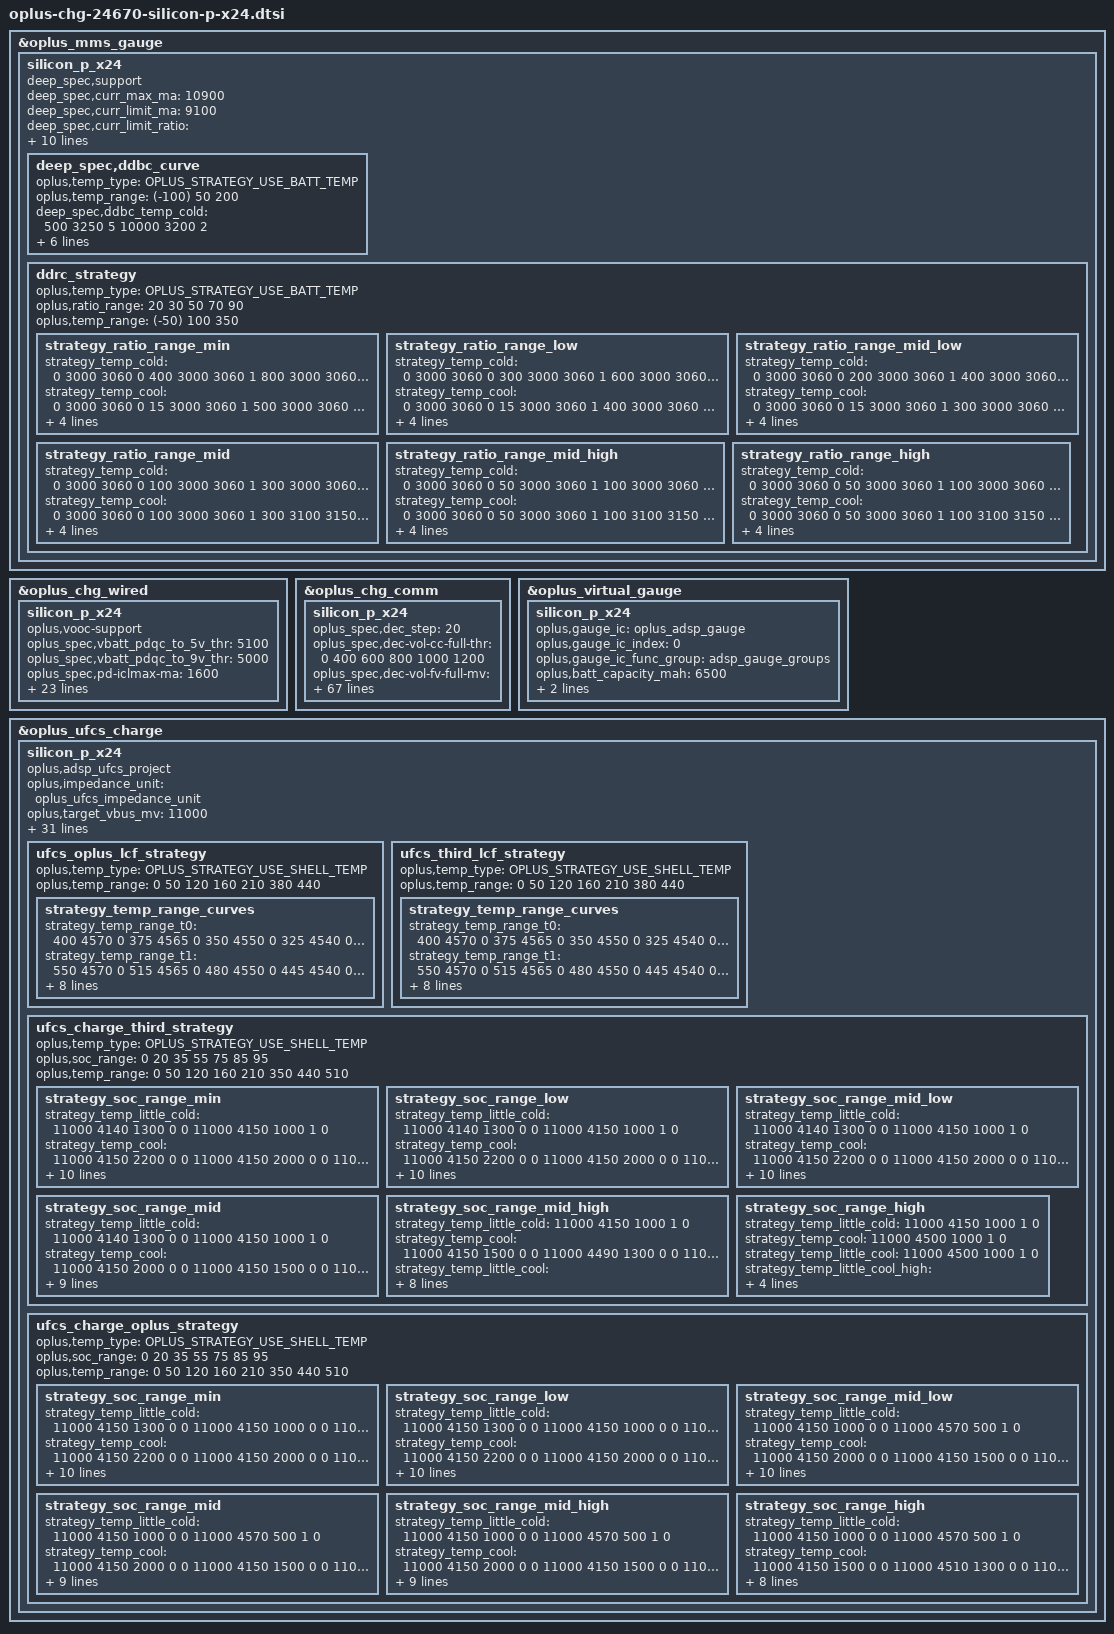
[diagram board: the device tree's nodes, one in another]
//ifdef OPLUS_FEATURE_CHG_BASIC

&oplus_mms_gauge {
	silicon_p_x24 {
		deep_spec,support;

		deep_spec,curr_max_ma = <10900>;
		deep_spec,curr_limit_ma = <9100>;
		deep_spec,curr_limit_ratio = <20 100 0
					50 30 1
					500 60 2
					500 60 3>;

		deep_spec,uv_thr = <3000>;
		deep_spec,count_thr = <50>;
		deep_spec,vbat_soc = <20>;
		deep_spec,count_step = <0 10 0
					350 12 1
					450 15 2
					530 20 3>;

		deep_spec,term_coeff = <3000 320 0
					3050 440 2
					3060 440 2
					3150 540 4
					3250 580 5
					3350 600 7>;
		deep_spec,ddrc_strategy_name = "ddrc_curve";
		deep_spec,volt_step = <20>;
		deep_spec,ddbc_curve {
			oplus,temp_type = <OPLUS_STRATEGY_USE_BATT_TEMP>;
			oplus,temp_range = <(-100) 50 200>;
			deep_spec,ddbc_temp_cold = <500 3250 5
						   10000 3200 2>;
			deep_spec,ddbc_temp_cool = <500 3250 5
						   10000 3200 2>;
			deep_spec,ddbc_temp_normal = <500 3350 5
						   10000 3300 2>;
			deep_spec,ddbc_temp_warm = <500 3350 5
						   10000 3300 2>;
		};
		ddrc_strategy {
			oplus,temp_type = <OPLUS_STRATEGY_USE_BATT_TEMP>;
			oplus,ratio_range = <20 30 50 70 90>;
			oplus,temp_range = <(-50) 100 350>;
			strategy_ratio_range_min {
				strategy_temp_cold =	<0 3000 3060 0
							400 3000 3060 1
							800 3000 3060 2
							1200 3100 3150 3
							1600 3200 3250 4
							2000 3300 3350 5>;
				strategy_temp_cool =	<0 3000 3060 0
							15 3000 3060 1
							500 3000 3060 2
							1000 3100 3150 3
							1500 3200 3250 4
							2000 3300 3350 5>;
				strategy_temp_normal =	<0 3000 3060 0
							15 3000 3060 1
							500 3100 3150 2
							1000 3200 3250 3
							1500 3300 3350 4>;
				strategy_temp_warm =	<0 3000 3060 0
							15 3000 3060 1
							500 3100 3150 2
							1000 3200 3250 3
							1500 3300 3350 4>;
			};
			strategy_ratio_range_low {
				strategy_temp_cold =	<0 3000 3060 0
							300 3000 3060 1
							600 3000 3060 2
							900 3100 3150 3
							1200 3200 3250 4
							1600 3300 3350 5>;
				strategy_temp_cool =	<0 3000 3060 0
							15 3000 3060 1
							400 3000 3060 2
							800 3100 3150 3
							1200 3200 3250 4
							1600 3300 3350 5 >;
				strategy_temp_normal =	<0 3000 3060 0
							15 3000 3060 1
							400 3100 3150 2
							800 3200 3250 3
							1200 3300 3350 4>;
				strategy_temp_warm =	<0 3000 3060 0
							15 3000 3060 1
							400 3100 3150 2
							800 3200 3250 3
							1200 3300 3350 4>;
			};
			strategy_ratio_range_mid_low {
				strategy_temp_cold =	<0 3000 3060 0
							200 3000 3060 1
							400 3000 3060 2
							600 3100 3150 3
							900 3200 3250 4
							1200 3300 3350 5>;
				strategy_temp_cool =	<0 3000 3060 0
							15 3000 3060 1
							300 3000 3060 2
							600 3100 3150 3
							900 3200 3250 4
							1200 3300 3350 5>;
				strategy_temp_normal =	<0 3000 3060 0
							15 3000 3060 1
							300 3100 3150 2
							600 3200 3250 3
							900 3300 3350 4>;
				strategy_temp_warm =	<0 3000 3060 0
							15 3000 3060 1
							300 3100 3150 2
							600 3200 3250 3
							900 3300 3350 4>;
			};
			strategy_ratio_range_mid {
				strategy_temp_cold =	<0 3000 3060 0
							100 3000 3060 1
							300 3000 3060 2
							500 3100 3150 3
							700 3200 3250 4
							900 3300 3350 5>;
				strategy_temp_cool =	<0 3000 3060 0
							100 3000 3060 1
							300 3100 3150 2
							600 3200 3250 3
							900 3300 3350 4>;
				strategy_temp_normal =	<0 3000 3060 0
							100 3100 3150 1
							300 3200 3250 2
							600 3300 3350 3>;
				strategy_temp_warm =	<0 3000 3060 0
							100 3100 3150 1
							300 3200 3250 2
							600 3300 3350 3>;
			};
			strategy_ratio_range_mid_high {
				strategy_temp_cold =	<0 3000 3060 0
							50 3000 3060 1
							100 3000 3060 2
							150 3100 3150 3
							300 3200 3250 4
							500 3300 3350 5>;
				strategy_temp_cool =	<0 3000 3060 0
							50 3000 3060 1
							100 3100 3150 2
							150 3200 3250 3
							300 3300 3350 4>;
				strategy_temp_normal =	<0 3000 3060 0
							50 3100 3150 1
							100 3200 3250 2
							150 3300 3350 3>;
				strategy_temp_warm =	<0 3000 3060 0
							50 3100 3150 1
							100 3200 3250 2
							150 3300 3350 3>;
			};
			strategy_ratio_range_high {
				strategy_temp_cold =	<0 3000 3060 0
							50 3000 3060 1
							100 3000 3060 2
							150 3100 3150 3
							300 3200 3250 4
							500 3300 3350 5>;
				strategy_temp_cool =	<0 3000 3060 0
							50 3000 3060 1
							100 3100 3150 2
							150 3200 3250 3
							300 3300 3350 4>;
				strategy_temp_normal =	<0 3000 3060 0
							50 3100 3150 1
							100 3200 3250 2
							150 3300 3350 3>;
				strategy_temp_warm =	<0 3000 3060 0
							50 3100 3150 1
							100 3200 3250 2
							150 3300 3350 3>;
			};
		};
	};
};


&oplus_chg_wired {
	silicon_p_x24 {
		oplus,vooc-support;

		oplus_spec,vbatt_pdqc_to_5v_thr = <5100>;
		oplus_spec,vbatt_pdqc_to_9v_thr = <5000>;
		oplus_spec,pd-iclmax-ma = <1600>;
		oplus_spec,qc-iclmax-ma = <1600>;
		oplus_spec,non-standard-ibatmax-ma = <500>;
		oplus_spec,input-power-mw = <
			2500		/* OPLUS_WIRED_CHG_MODE_UNKNOWN */
			2500		/* OPLUS_WIRED_CHG_MODE_SDP */
			7500		/* OPLUS_WIRED_CHG_MODE_CDP */
			10000		/* OPLUS_WIRED_CHG_MODE_DCP */
			15000		/* OPLUS_WIRED_CHG_MODE_VOOC */
			14400		/* OPLUS_WIRED_CHG_MODE_QC */
			14400		/* OPLUS_WIRED_CHG_MODE_PD */
		>;
		oplus_spec,led_on-fccmax-ma = <0 273 1364 1760 1760 1760 1760 500 0>;
		oplus_spec,fccmax-ma-lv = <
			0 273 1100 1100 1100 1100 1100 1100  0	/* OPLUS_WIRED_CHG_MODE_UNKNOWN */
			0 273  300  300  300  300  300  300  0	/* OPLUS_WIRED_CHG_MODE_SDP */
			0 273  800  800  800  800  800  800  0	/* OPLUS_WIRED_CHG_MODE_CDP */
			0 273  1100 1100 1100 1100 1100 1100 0	/* OPLUS_WIRED_CHG_MODE_DCP */
			0 273  1364 1650 1650 1650 1650 1650 0	/* OPLUS_WIRED_CHG_MODE_VOOC */
			0 273  1364 1760 1760 1760 1760 1667 0	/* OPLUS_WIRED_CHG_MODE_QC */
			0 273  1364 1760 1760 1760 1760 1667 0	/* OPLUS_WIRED_CHG_MODE_PD */
		>;
		oplus_spec,fccmax-ma-hv = <
			0 273  545  818 1100 1100 1100  1100 0	/* OPLUS_WIRED_CHG_MODE_UNKNOWN */
			0 273  300  300  300  300  300  300  0	/* OPLUS_WIRED_CHG_MODE_SDP */
			0 273  545  800  800  800  800  800  0	/* OPLUS_WIRED_CHG_MODE_CDP */
			0 273  545  818  1100 1100 1100 1100 0	/* OPLUS_WIRED_CHG_MODE_DCP */
			0 273  545  818  1364 1650 1650 1650 0	/* OPLUS_WIRED_CHG_MODE_VOOC */
			0 273  545  818  1364 1760 1760 1667 0	/* OPLUS_WIRED_CHG_MODE_QC */
			0 273  545  818  1364 1760 1760 1667 0	/* OPLUS_WIRED_CHG_MODE_PD */
		>;

		oplus_spec,cool_down_pdqc_vol_mv = <9000 9000 9000>;
		oplus_spec,cool_down_pdqc_curr_ma = <1200 1600 1600>;
		oplus_spec,cool_down_vooc_curr_ma = <1200 1500 2000 2500 3000 3000>;
		oplus_spec,cool_down_normal_curr_ma = <1200 1500 2000>;

		oplus_spec,vbus_ov_thr_mv = <11000 11000>;
		oplus_spec,vbus_uv_thr_mv = <4300 4300>;

		/* first data is strategy used temp type */
		oplus,vooc_strategy_name = "cgcl";
		oplus,vooc_strategy_data = <OPLUS_STRATEGY_USE_BATT_TEMP
					    0   350 3600 1 0
					    330 370 3200 2 0
					    350 440 2200 2 1>;
	};
};
&oplus_chg_comm {
	silicon_p_x24 {
		oplus_spec,dec_step = <20>;
		oplus_spec,dec-vol-cc-full-thr = <0 400 600 800 1000 1200>;
		oplus_spec,dec-vol-fv-full-mv = <0 20 20 40 40 40>;
		oplus_spec,batt-them-thr = <(-100) 0 50 120 160 350 450 530>;
		oplus_spec,iterm-ma = <162>;
		oplus_spec,fv-mv = <4500 4500 4500 4500 4500 4500 4475 4130 4130>;
		oplus_spec,sw-fv-mv = <4450 4450 4450 4450 4450 4450 4425 4080 4080>;
		oplus_spec,hw-fv-inc-mv = <0 18 18 18 18 18 18 18 0>;
		oplus_spec,sw-over-fv-mv = <4510 4510 4510 4510 4510 4510 4485 4140 4140>;
		oplus_spec,sw-over-fv-dec-mv = <8>;
		oplus_spec,non-standard-sw-fv-mv = <3930>;
		oplus_spec,non-standard-fv-mv = <3980>;
		oplus_spec,non-standard-hw-fv-inc-mv = <18>;
		oplus_spec,non-standard-sw-over-fv-mv = <3990>;
		oplus_spec,non-standard-vbatdet-mv = <3680>;
		oplus_spec,wired-vbatdet-mv = <0 4200 4300 4400 4400 4400 4375 4030 0>;
		oplus_spec,fcc-gear-thr-mv = <4180>;
		oplus_spec,fcc-gear-shake-mv = <400 400 400 300 300 180 180 180 180>;
		oplus_spec,vbatt-ov-thr-mv = <4600>;

		oplus_spec,full_pre_ffc_judge;
		oplus_spec,full-pre-ffc-mv = <4495>;
		oplus_spec,ffc-temp-thr = <120 210 350 440>;
		oplus_spec,wired-ffc-step-max = <2>;
		oplus_spec,wired-ffc-fv-mv = <4590 4590>;

		oplus_spec,wired-ffc-fv-cutoff-mv = <4550 4525 4490
						     4520 4505 4475>;

		oplus_spec,removed_bat_decidegc = <390>;

		oplus_spec,wired-ffc-fcc-ma = <550 550 550
					       350 350 350>;
		oplus_spec,wired-ffc-fcc-cutoff-ma = <400 400 400
						      200 200 200>;

		oplus_spec,drop_soc_2_temp_ladder = <(-50) 0 0 0 0 0 0 0 0 0>;
		oplus_spec,volt_diff_ladder_of_drop_soc_2 = <20 50 0 0 0 0 0 0 0 0>;
		oplus_spec,keep_soc_2_temp_ladder = <(-200) (-50) 0 0 0 0 0 0 0 0>;
		oplus_spec,volt_diff_ladder_of_keep_soc_2 = <10 20 30 0 0 0 0 0 0 0>;
		oplus_spec,back_rm_of_drop_soc_2 = <60>;
		oplus_spec,back_rm_of_drop_soc_1 = <60>;
		oplus_spec,load_current_of_drop_soc_2 = <500>;
		oplus_spec,load_current_of_drop_soc_1 = <1000>;
		oplus_spec,current_limit_of_drop_soc_2 = <350>;
		oplus_spec,volt_of_fast_drop_soc_1 = <2900>;
		oplus_spec,support_uisoc_low_battery_control;


		oplus_spec,vbat_uv_thr_mv = <3000>;
		oplus_spec,vbat_charging_uv_thr_mv = <2900>;

		/*If use subboard NTC as battery temp, config it as 20, otherwise 0 */
		oplus_spec,tbatt_power_off_cali_temp = <0>;
		oplus,vooc_show_ui_soc_decimal;
		oplus_spec,poweroff_high_batt_temp = <720>;
		oplus_spec,poweroff_emergency_batt_temp = <770>;
		oplus,ui_soc_decimal_speedmin = <20>;

		oplus,gauge_stuck_jump_support;
		oplus,gauge_stuck_threshold = <15>;
		oplus,gauge_stuck_time = <50>;

		oplus_spec,sw_check_full_cnt = <12>;
		oplus,hidden_soc_switch;
		oplus,reserve_chg_soc = <3>;
		oplus,hidden_soc_percent = <20>;


		oplus,ui_soc_2_voltage_comp_mv = <30>;
		oplus,chg_shutdown_max_mv = <3000>;
	};
};

&oplus_virtual_gauge {
	silicon_p_x24 {
			oplus,gauge_ic = <&oplus_adsp_gauge>;
			oplus,gauge_ic_index = <0>;
			oplus,gauge_ic_func_group = <&adsp_gauge_groups>;
			oplus,batt_capacity_mah = <6500>;
			oplus,ic_type = <OPLUS_CHG_IC_VIRTUAL_GAUGE>;
			oplus,ic_index = <0>;
	};
};
&oplus_ufcs_charge {
	silicon_p_x24 {
		oplus,adsp_ufcs_project;
		oplus,impedance_unit = <&oplus_ufcs_impedance_unit>;

		oplus,target_vbus_mv = <11000>;
		oplus,curr_max_ma = <10900>;
		oplus,subboard_ntc_abnormal_current = <7300>;
		oplus,ufcs_warm_allow_vol = <4000>;
		oplus,ufcs_warm_allow_soc = <55>;
		oplus,ufcs_strategy_normal_current = <10900>;
		oplus,ufcs_over_high_or_low_current = <3000>;
		oplus,ufcs_timeout_third = <15582>;
		oplus,ufcs_timeout_oplus = <15582>;
		oplus,ufcs_ibat_over_third = <5400>;
		oplus,ufcs_ibat_over_oplus = <12300>;
		oplus,ufcs_ibus_over_oplus = <12300>;
		oplus,ufcs_full_cool_sw_vbat = <4570>;
		oplus,ufcs_full_normal_sw_vbat = <4570>;
		oplus,ufcs_full_normal_hw_vbat = <4580>;
		oplus,ufcs_full_ffc_vbat = <4540>;
		oplus,ufcs_full_warm_vbat = <4130>;
		oplus,ufcs_full_cool_sw_vbat_third = <4470>;
		oplus,ufcs_full_normal_sw_vbat_third= <4470>;
		oplus,ufcs_full_normal_hw_vbat_third = <4480>;
		oplus,ufcs_current_change_timeout = <100>;
		oplus,ufcs_strategy_batt_high_temp = <400 420 430 380 400 420>;
		oplus,ufcs_strategy_high_current = <7000 4000 3000 8000 6000 4000>;
		oplus,ufcs_little_cool_high_temp = <210>;
		oplus,curve_strategy_name = "pps_ufcs_curve_v2";
		oplus_spec,ufcs_high_soc = <95>;
		oplus,ufcs_charge_strategy_soc = <0 20 35 55 75 85 95>;
		oplus,ufcs_charge_strategy_temp = <0 50 120 160 350 440 510>;
		ufcs_oplus_lcf_strategy {
			oplus,temp_type = <OPLUS_STRATEGY_USE_SHELL_TEMP>;
			oplus,temp_range = <0 50 120 160 210 380 440>;

			strategy_temp_range_curves {
				strategy_temp_range_t0 =	<400 4570 0
								 375 4565 0
								 350 4550 0
								 325 4540 0
								 300 4530 1>;
				strategy_temp_range_t1 =	<550 4570 0
								 515 4565 0
								 480 4550 0
								 445 4540 0
								 410 4530 1>;
				strategy_temp_range_t2 =	<700 4570 0
								 655 4565 0
								 610 4550 0
								 565 4540 0
								 520 4530 1>;
				strategy_temp_range_t3 =	<850 4570 0
								 800 4565 0
								 700 4550 0
								 600 4540 0
								 450 4530 1>;
				strategy_temp_range_t4 =	<1400 4570 0
								 1350 4565 0
								 1250 4550 0
								 1150 4540 0
								 1000 4530 1>;
				strategy_temp_range_t5 =	<2300 4570 0
								 2250 4565 0
								 2150 4550 0
								 2050 4540 0
								 1900 4530 1>;
			};
		};

		ufcs_third_lcf_strategy {
			oplus,temp_type = <OPLUS_STRATEGY_USE_SHELL_TEMP>;
			oplus,temp_range = <0 50 120 160 210 380 440>;

			strategy_temp_range_curves {
				strategy_temp_range_t0 =	<400 4570 0
								 375 4565 0
								 350 4550 0
								 325 4540 0
								 300 4530 1>;
				strategy_temp_range_t1 =	<550 4570 0
								 515 4565 0
								 480 4550 0
								 445 4540 0
								 410 4530 1>;
				strategy_temp_range_t2 =	<700 4570 0
								 655 4565 0
								 610 4550 0
								 565 4540 0
								 520 4530 1>;
				strategy_temp_range_t3 =	<850 4570 0
								 800 4565 0
								 700 4550 0
								 600 4540 0
								 450 4530 1>;
				strategy_temp_range_t4 =	<1400 4570 0
								 1350 4565 0
								 1250 4550 0
								 1150 4540 0
								 1000 4530 1>;
				strategy_temp_range_t5 =	<2300 4570 0
								 2250 4565 0
								 2150 4550 0
								 2050 4540 0
								 1900 4530 1>;
			};
		};

		ufcs_charge_third_strategy {
			oplus,temp_type = <OPLUS_STRATEGY_USE_SHELL_TEMP>;
			oplus,soc_range = <0 20 35 55 75 85 95>;
			oplus,temp_range = <0 50 120 160 210 350 440 510>;

			strategy_soc_range_min {
				strategy_temp_little_cold =	<11000 4140 1300 0 0
								11000 4150 1000 1 0>;
				strategy_temp_cool =		<11000 4150 2200 0 0
								11000 4150 2000 0 0
								11000 4150 1500 0 0
								11000 4490 1300 0 0
								11000 4500 1000 1 0>;
				strategy_temp_little_cool =	<11000 4150 2900 0 0
								11000 4150 2500 0 0
								11000 4330 2200 0 0
								11000 4330 2000 0 0
								11000 4330 1500 0 0
								11000 4490 1300 0 0
								11000 4500 1000 1 0>;
				strategy_temp_little_cool_high = <11000 4280 4000 0 0
								11000 4280 3500 0 0
								11000 4490 3400 0 0
								11000 4490 3000 0 0
								11000 4490 2900 0 0
								11000 4490 2500 0 0
								11000 4490 2000 0 0
								11000 4490 1500 0 0
								11000 4500 1000 1 0>;
				strategy_temp_normal_low =	<11000 4430 4000 0 0
								11000 4430 3500 0 0
								11000 4490 3400 0 0
								11000 4490 3000 0 0
								11000 4490 2500 0 0
								11000 4490 2000 0 0
								11000 4490 1500 0 0
								11000 4500 1000 1 0>;
				strategy_temp_normal_high =	<11000 4430 4000 0 0
								11000 4430 3500 0 0
								11000 4490 3400 0 0
								11000 4490 3000 0 0
								11000 4490 2500 0 0
								11000 4490 2000 0 0
								11000 4490 1500 0 0
								11000 4500 1000 1 0>;
				strategy_temp_warm =		<11000 4120 1600 0 0
								11000 4120 1500 0 0
								11000 4130 1000 1 0>;
			};
			strategy_soc_range_low {
				strategy_temp_little_cold =	<11000 4140 1300 0 0
								11000 4150 1000 1 0>;
				strategy_temp_cool =		<11000 4150 2200 0 0
								11000 4150 2000 0 0
								11000 4150 1500 0 0
								11000 4490 1300 0 0
								11000 4500 1000 1 0>;
				strategy_temp_little_cool =	<11000 4150 2900 0 0
								11000 4150 2500 0 0
								11000 4330 2200 0 0
								11000 4330 2000 0 0
								11000 4330 1500 0 0
								11000 4490 1300 0 0
								11000 4500 1000 1 0>;
				strategy_temp_little_cool_high = <11000 4280 4000 0 0
								11000 4280 3500 0 0
								11000 4490 3400 0 0
								11000 4490 3000 0 0
								11000 4490 2900 0 0
								11000 4490 2500 0 0
								11000 4490 2000 0 0
								11000 4490 1500 0 0
								11000 4500 1000 1 0>;
				strategy_temp_normal_low =	<11000 4430 4000 0 0
								11000 4430 3500 0 0
								11000 4490 3400 0 0
								11000 4490 3000 0 0
								11000 4490 2500 0 0
								11000 4490 2000 0 0
								11000 4490 1500 0 0
								11000 4500 1000 1 0>;
				strategy_temp_normal_high =	<11000 4430 4000 0 0
								11000 4430 3500 0 0
								11000 4465 3400 0 0
								11000 4465 3000 0 0
								11000 4465 2500 0 0
								11000 4465 2000 0 0
								11000 4465 1500 0 0
								11000 4475 1000 1 0>;
				strategy_temp_warm =		<11000 4120 1600 0 0
								11000 4120 1500 0 0
								11000 4130 1000 1 0>;
			};
			strategy_soc_range_mid_low {
				strategy_temp_little_cold =	<11000 4140 1300 0 0
								11000 4150 1000 1 0>;
				strategy_temp_cool =		<11000 4150 2200 0 0
								11000 4150 2000 0 0
								11000 4150 1500 0 0
								11000 4490 1300 0 0
								11000 4500 1000 1 0>;
				strategy_temp_little_cool =	<11000 4150 2900 0 0
								11000 4150 2500 0 0
								11000 4330 2200 0 0
								11000 4330 2000 0 0
								11000 4330 1500 0 0
								11000 4490 1300 0 0
								11000 4500 1000 1 0>;
				strategy_temp_little_cool_high = <11000 4280 4000 0 0
								11000 4280 3500 0 0
								11000 4490 3400 0 0
								11000 4490 3000 0 0
								11000 4490 2900 0 0
								11000 4490 2500 0 0
								11000 4490 2000 0 0
								11000 4490 1500 0 0
								11000 4500 1000 1 0>;
				strategy_temp_normal_low =	<11000 4430 4000 0 0
								11000 4430 3500 0 0
								11000 4490 3400 0 0
								11000 4490 3000 0 0
								11000 4490 2500 0 0
								11000 4490 2000 0 0
								11000 4490 1500 0 0
								11000 4500 1000 1 0>;
				strategy_temp_normal_high =	<11000 4430 4000 0 0
								11000 4430 3500 0 0
								11000 4465 3400 0 0
								11000 4465 3000 0 0
								11000 4465 2500 0 0
								11000 4465 2000 0 0
								11000 4465 1500 0 0
								11000 4475 1000 1 0>;
				strategy_temp_warm =		<11000 4120 1600 0 0
								11000 4120 1500 0 0
								11000 4130 1000 1 0>;
			};
			strategy_soc_range_mid {
				strategy_temp_little_cold =	<11000 4140 1300 0 0
								11000 4150 1000 1 0>;
				strategy_temp_cool =		<11000 4150 2000 0 0
								11000 4150 1500 0 0
								11000 4490 1300 0 0
								11000 4500 1000 1 0>;
				strategy_temp_little_cool =	<11000 4150 2900 0 0
								11000 4150 2500 0 0
								11000 4330 2200 0 0
								11000 4330 2000 0 0
								11000 4330 1500 0 0
								11000 4490 1300 0 0
								11000 4500 1000 1 0>;
				strategy_temp_little_cool_high = <11000 4490 3000 0 0
								11000 4490 2900 0 0
								11000 4490 2500 0 0
								11000 4490 2000 0 0
								11000 4490 1500 0 0
								11000 4500 1000 1 0>;
				strategy_temp_normal_low =	<11000 4430 3500 0 0
								11000 4490 3400 0 0
								11000 4490 3000 0 0
								11000 4490 2500 0 0
								11000 4490 2000 0 0
								11000 4490 1500 0 0
								11000 4500 1000 1 0>;
				strategy_temp_normal_high =	<11000 4430 4000 0 0
								11000 4430 3500 0 0
								11000 4465 3400 0 0
								11000 4465 3000 0 0
								11000 4465 2500 0 0
								11000 4465 2000 0 0
								11000 4465 1500 0 0
								11000 4475 1000 1 0>;
				strategy_temp_warm =		<11000 4130 1000 1 0>;
			};
			strategy_soc_range_mid_high {
				strategy_temp_little_cold =	<11000 4150 1000 1 0>;
				strategy_temp_cool =		<11000 4150 1500 0 0
								11000 4490 1300 0 0
								11000 4500 1000 1 0>;
				strategy_temp_little_cool =	<11000 4330 2000 0 0
								11000 4330 1500 0 0
								11000 4490 1300 0 0
								11000 4500 1000 1 0>;
				strategy_temp_little_cool_high = <11000 4490 2000 0 0
								11000 4490 1500 0 0
								11000 4500 1000 1 0>;
				strategy_temp_normal_low =	<11000 4490 2500 0 0
								11000 4490 2000 0 0
								11000 4490 1500 0 0
								11000 4500 1000 1 0>;
				strategy_temp_normal_high =	<11000 4465 2500 0 0
								11000 4475 2000 0 0
								11000 4475 1500 0 0
								11000 4475 1000 1 0>;
				strategy_temp_warm =		<11000 4130 1000 1 0>;
			};
			strategy_soc_range_high {
				strategy_temp_little_cold =	<11000 4150 1000 1 0>;
				strategy_temp_cool =		<11000 4500 1000 1 0>;
				strategy_temp_little_cool =	<11000 4500 1000 1 0>;
				strategy_temp_little_cool_high = <11000 4500 1000 1 0>;
				strategy_temp_normal_low =	<11000 4500 1000 1 0>;
				strategy_temp_normal_high =	<11000 4475 1000 1 0>;
				strategy_temp_warm =		<11000 4130 1000 1 0>;
			};
		};

		ufcs_charge_oplus_strategy {
			oplus,temp_type = <OPLUS_STRATEGY_USE_SHELL_TEMP>;
			oplus,soc_range = <0 20 35 55 75 85 95>;
			oplus,temp_range = <0 50 120 160 210 350 440 510>;

			strategy_soc_range_min {
				strategy_temp_little_cold =	<11000 4150 1300 0 0
								11000 4150 1000 0 0
								11000 4570 500 1 0>;
				strategy_temp_cool =		<11000 4150 2200 0 0
								11000 4150 2000 0 0
								11000 4150 1500 0 0
								11000 4510 1300 0 0
								11000 4510 1000 0 0
								11000 4560 700 0 0
								11000 4570 600 1 0>;
				strategy_temp_little_cool =	<11000 4150 2900 0 0
								11000 4150 2500 0 0
								11000 4330 2200 0 0
								11000 4330 2000 0 0
								11000 4330 1500 0 0
								11000 4560 1300 0 0
								11000 4560 1000 0 0
								11000 4570 700 1 0>;
				strategy_temp_little_cool_high = <11000 4150 5800 0 60
								11000 4150 5500 0 0
								11000 4150 5000 0 0
								11000 4150 4500 0 0
								11000 4280 4300 0 0
								11000 4280 4000 0 0
								11000 4280 3500 0 0
								11000 4510 3400 0 0
								11000 4510 3000 0 0
								11000 4560 2900 0 0
								11000 4560 2500 0 0
								11000 4560 2000 0 0
								11000 4560 1500 0 0
								11000 4560 1000 0 0
								11000 4570 900 1 0>;
				strategy_temp_normal_low =	<11000 4100 10900 0 10
								11000 4100 9100 0 50
								11000 4140 8700 0 0
								11000 4140 8500 0 0
								11000 4140 8000 0 0
								11000 4230 7800 0 0
								11000 4230 7500 0 0
								11000 4230 7000 0 0
								11000 4230 6500 0 0
								11000 4230 6000 0 0
								11000 4430 5800 0 0
								11000 4430 5500 0 0
								11000 4430 5000 0 0
								11000 4430 4500 0 0
								11000 4430 4000 0 0
								11000 4430 3500 0 0
								11000 4560 3400 0 0
								11000 4560 3000 0 0
								11000 4560 2500 0 0
								11000 4560 2000 0 0
								11000 4570 1500 1 0>;
				strategy_temp_normal_high =	<11000 4100 10900 0 10
								11000 4100 9100 0 50
								11000 4140 8700 0 0
								11000 4140 8500 0 0
								11000 4140 8000 0 0
								11000 4230 7800 0 0
								11000 4230 7500 0 0
								11000 4230 7000 0 0
								11000 4230 6500 0 0
								11000 4230 6000 0 0
								11000 4430 5800 0 0
								11000 4430 5500 0 0
								11000 4430 5000 0 0
								11000 4430 4500 0 0
								11000 4430 4000 0 0
								11000 4430 3500 0 0
								11000 4560 3400 0 0
								11000 4560 3000 0 0
								11000 4560 2500 0 0
								11000 4570 2400 1 0>;
				strategy_temp_warm =		<11000 4120 1600 0 0
								11000 4120 1500 0 0
								11000 4120 1000 0 0
								11000 4130 500 1 0>;
			};
			strategy_soc_range_low {
				strategy_temp_little_cold =	<11000 4150 1300 0 0
								11000 4150 1000 0 0
								11000 4570 500 1 0>;
				strategy_temp_cool =		<11000 4150 2200 0 0
								11000 4150 2000 0 0
								11000 4150 1500 0 0
								11000 4510 1300 0 0
								11000 4510 1000 0 0
								11000 4560 700 0 0
								11000 4570 600 1 0>;
				strategy_temp_little_cool =	<11000 4150 2900 0 0
								11000 4150 2500 0 0
								11000 4330 2200 0 0
								11000 4330 2000 0 0
								11000 4330 1500 0 0
								11000 4560 1300 0 0
								11000 4560 1000 0 0
								11000 4570 700 1 0>;
				strategy_temp_little_cool_high = <11000 4150 5800 0 60
								11000 4150 5500 0 0
								11000 4150 5000 0 0
								11000 4150 4500 0 0
								11000 4280 4300 0 0
								11000 4280 4000 0 0
								11000 4280 3500 0 0
								11000 4510 3400 0 0
								11000 4510 3000 0 0
								11000 4560 2900 0 0
								11000 4560 2500 0 0
								11000 4560 2000 0 0
								11000 4560 1500 0 0
								11000 4560 1000 0 0
								11000 4570 900 1 0>;
				strategy_temp_normal_low =	<11000 4100 9100 0 60
								11000 4140 8700 0 0
								11000 4140 8500 0 0
								11000 4140 8000 0 0
								11000 4230 7800 0 0
								11000 4230 7500 0 0
								11000 4230 7000 0 0
								11000 4230 6500 0 0
								11000 4230 6000 0 0
								11000 4430 5800 0 0
								11000 4430 5500 0 0
								11000 4430 5000 0 0
								11000 4430 4500 0 0
								11000 4430 4000 0 0
								11000 4430 3500 0 0
								11000 4560 3400 0 0
								11000 4560 3000 0 0
								11000 4560 2500 0 0
								11000 4560 2000 0 0
								11000 4570 1500 1 0>;
				strategy_temp_normal_high =	<11000 4100 9100 0 60
								11000 4140 8700 0 0
								11000 4140 8500 0 0
								11000 4140 8000 0 0
								11000 4230 7800 0 0
								11000 4230 7500 0 0
								11000 4230 7000 0 0
								11000 4230 6500 0 0
								11000 4230 6000 0 0
								11000 4430 5800 0 0
								11000 4430 5500 0 0
								11000 4430 5000 0 0
								11000 4430 4500 0 0
								11000 4430 4000 0 0
								11000 4430 3500 0 0
								11000 4560 3400 0 0
								11000 4560 3000 0 0
								11000 4560 2500 0 0
								11000 4570 2400 1 0>;
				strategy_temp_warm =		<11000 4120 1600 0 0
								11000 4120 1500 0 0
								11000 4120 1000 0 0
								11000 4130 500 1 0>;
			};
			strategy_soc_range_mid_low {
				strategy_temp_little_cold =	<11000 4150 1000 0 0
								11000 4570 500 1 0>;
				strategy_temp_cool =		<11000 4150 2000 0 0
								11000 4150 1500 0 0
								11000 4510 1300 0 0
								11000 4510 1000 0 0
								11000 4560 700 0 0
								11000 4570 600 1 0>;
				strategy_temp_little_cool =	<11000 4150 2900 0 0
								11000 4150 2500 0 0
								11000 4330 2200 0 0
								11000 4330 2000 0 0
								11000 4330 1500 0 0
								11000 4560 1300 0 0
								11000 4560 1000 0 0
								11000 4570 700 1 0>;
				strategy_temp_little_cool_high = <11000 4150 5800 0 60
								11000 4150 5500 0 0
								11000 4150 5000 0 0
								11000 4150 4500 0 0
								11000 4280 4300 0 0
								11000 4280 4000 0 0
								11000 4280 3500 0 0
								11000 4510 3400 0 0
								11000 4510 3000 0 0
								11000 4560 2900 0 0
								11000 4560 2500 0 0
								11000 4560 2000 0 0
								11000 4560 1500 0 0
								11000 4560 1000 0 0
								11000 4570 900 1 0>;
				strategy_temp_normal_low =	<11000 4100 9100 0 60
								11000 4140 8700 0 0
								11000 4140 8500 0 0
								11000 4140 8000 0 0
								11000 4230 7800 0 0
								11000 4230 7500 0 0
								11000 4230 7000 0 0
								11000 4230 6500 0 0
								11000 4230 6000 0 0
								11000 4430 5800 0 0
								11000 4430 5500 0 0
								11000 4430 5000 0 0
								11000 4430 4500 0 0
								11000 4430 4000 0 0
								11000 4430 3500 0 0
								11000 4560 3400 0 0
								11000 4560 3000 0 0
								11000 4560 2500 0 0
								11000 4560 2000 0 0
								11000 4570 1500 1 0>;
				strategy_temp_normal_high =	<11000 4100 9100 0 60
								11000 4140 8700 0 0
								11000 4140 8500 0 0
								11000 4140 8000 0 0
								11000 4230 7800 0 0
								11000 4230 7500 0 0
								11000 4230 7000 0 0
								11000 4230 6500 0 0
								11000 4230 6000 0 0
								11000 4430 5800 0 0
								11000 4430 5500 0 0
								11000 4430 5000 0 0
								11000 4430 4500 0 0
								11000 4430 4000 0 0
								11000 4430 3500 0 0
								11000 4560 3400 0 0
								11000 4560 3000 0 0
								11000 4560 2500 0 0
								11000 4570 2400 1 0>;
				strategy_temp_warm =		<11000 4120 1600 0 0
								11000 4120 1500 0 0
								11000 4120 1000 0 0
								11000 4130 500 1 0>;
			};
			strategy_soc_range_mid {
				strategy_temp_little_cold =	<11000 4150 1000 0 0
								11000 4570 500 1 0>;
				strategy_temp_cool =		<11000 4150 2000 0 0
								11000 4150 1500 0 0
								11000 4510 1300 0 0
								11000 4510 1000 0 0
								11000 4560 700 0 0
								11000 4570 600 1 0>;
				strategy_temp_little_cool =	<11000 4150 2900 0 0
								11000 4150 2500 0 0
								11000 4330 2200 0 0
								11000 4330 2000 0 0
								11000 4330 1500 0 0
								11000 4560 1300 0 0
								11000 4560 1000 0 0
								11000 4570 700 1 0>;
				strategy_temp_little_cool_high = <11000 4280 4000 0 0
								11000 4280 3500 0 0
								11000 4510 3400 0 0
								11000 4510 3000 0 0
								11000 4560 2900 0 0
								11000 4560 2500 0 0
								11000 4560 2000 0 0
								11000 4560 1500 0 0
								11000 4560 1000 0 0
								11000 4570 900 1 0>;
				strategy_temp_normal_low =	<11000 4430 4500 0 0
								11000 4430 4000 0 0
								11000 4430 3500 0 0
								11000 4560 3400 0 0
								11000 4560 3000 0 0
								11000 4560 2500 0 0
								11000 4560 2000 0 0
								11000 4570 1500 1 0>;
				strategy_temp_normal_high =	<11000 4430 5000 0 0
								11000 4430 4500 0 0
								11000 4430 4000 0 0
								11000 4430 3500 0 0
								11000 4560 3400 0 0
								11000 4560 3000 0 0
								11000 4560 2500 0 0
								11000 4570 2400 1 0>;
				strategy_temp_warm =		<11000 4130 1000 1 0>;
			};
			strategy_soc_range_mid_high {
				strategy_temp_little_cold =	<11000 4150 1000 0 0
								11000 4570 500 1 0>;
				strategy_temp_cool =		<11000 4150 2000 0 0
								11000 4150 1500 0 0
								11000 4510 1300 0 0
								11000 4510 1000 0 0
								11000 4560 700 0 0
								11000 4570 600 1 0>;
				strategy_temp_little_cool =	<11000 4150 2900 0 0
								11000 4150 2500 0 0
								11000 4330 2200 0 0
								11000 4330 2000 0 0
								11000 4330 1500 0 0
								11000 4560 1300 0 0
								11000 4560 1000 0 0
								11000 4570 700 1 0>;
				strategy_temp_little_cool_high = <11000 4510 3000 0 0
								11000 4560 2900 0 0
								11000 4560 2500 0 0
								11000 4560 2000 0 0
								11000 4560 1500 0 0
								11000 4560 1000 0 0
								11000 4570 900 1 0>;
				strategy_temp_normal_low =	<11000 4430 3500 0 0
								11000 4560 3400 0 0
								11000 4560 3000 0 0
								11000 4560 2500 0 0
								11000 4560 2000 0 0
								11000 4570 1500 1 0>;
				strategy_temp_normal_high =	<11000 4430 3500 0 0
								11000 4560 3400 0 0
								11000 4560 3000 0 0
								11000 4560 2500 0 0
								11000 4570 2400 1 0>;
				strategy_temp_warm =		<11000 4130 1000 1 0>;
			};
			strategy_soc_range_high {
				strategy_temp_little_cold =	<11000 4150 1000 0 0
								11000 4570 500 1 0>;
				strategy_temp_cool =		<11000 4150 1500 0 0
								11000 4510 1300 0 0
								11000 4510 1000 0 0
								11000 4560 700 0 0
								11000 4570 600 1 0>;
				strategy_temp_little_cool =	<11000 4330 1500 0 0
								11000 4560 1300 0 0
								11000 4560 1000 0 0
								11000 4570 700 1 0>;
				strategy_temp_little_cool_high = <11000 4560 1500 0 0
								11000 4560 1000 0 0
								11000 4570 900 1 0>;
				strategy_temp_normal_low =	<11000 4560 2000 0 0
								11000 4570 1500 1 0>;
				strategy_temp_normal_high =	<11000 4570 2400 1 0>;
				strategy_temp_warm =		<11000 4130 1000 1 0>;
			};
		};
	};
};

//#endif
